# CY8C5868AXI_LP035 register map
File version: 0.1
CY8C58LP
Registers are 8-bit, read-write, no defined reset value unless marked. A register's access mark holds for its fields unless they carry their own. Offsets are from the block's base; lines under a group give offsets from that group; [hi:lo] are bit positions; {n}, {i} and the like mark numbered series; 'fields as' and 'values as' point back to an identical list; <NAME> marks a mode.

## Memory map
0x00000000 RECIBE — UART
0x00000000 EMITE — UART

## RECIBE — UART
Base 0x00000000
0x40006425 HD_RECIBE_RX_ADDRESS1 — RX Address1 Register
0x40006435 HD_RECIBE_RX_ADDRESS2 — RX Address2 Register
0x40006445 HD_RECIBE_RX_DATA — RX Data Register
0x40006455 HD_RECIBE_TX_DATA — TX Data Register
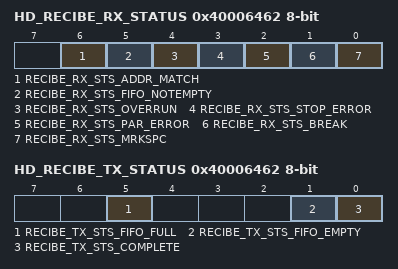
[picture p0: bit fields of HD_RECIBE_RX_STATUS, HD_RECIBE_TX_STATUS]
0x40006462 HD_RECIBE_RX_STATUS — RX status register
  [6] RECIBE_RX_STS_ADDR_MATCH ro, [5] RECIBE_RX_STS_FIFO_NOTEMPTY ro, [4] RECIBE_RX_STS_OVERRUN ro, [3] RECIBE_RX_STS_STOP_ERROR ro, [2] RECIBE_RX_STS_PAR_ERROR ro, [1] RECIBE_RX_STS_BREAK ro, [0] RECIBE_RX_STS_MRKSPC ro
0x40006462 HD_RECIBE_TX_STATUS — TX status register
  [5] RECIBE_TX_STS_FIFO_FULL ro, [1] RECIBE_TX_STS_FIFO_EMPTY ro, [0] RECIBE_TX_STS_COMPLETE ro

## EMITE — UART
Base 0x00000000
0x40006427 HD_EMITE_RX_ADDRESS1 — RX Address1 Register
0x40006437 HD_EMITE_RX_ADDRESS2 — RX Address2 Register
0x40006447 HD_EMITE_RX_DATA — RX Data Register
0x40006457 HD_EMITE_TX_DATA — TX Data Register
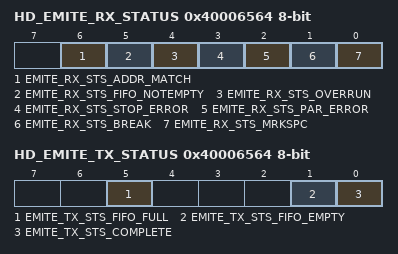
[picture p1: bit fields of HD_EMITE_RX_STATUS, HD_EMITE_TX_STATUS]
0x40006564 HD_EMITE_RX_STATUS — RX status register
  [6] EMITE_RX_STS_ADDR_MATCH ro, [5] EMITE_RX_STS_FIFO_NOTEMPTY ro, [4] EMITE_RX_STS_OVERRUN ro, [3] EMITE_RX_STS_STOP_ERROR ro, [2] EMITE_RX_STS_PAR_ERROR ro, [1] EMITE_RX_STS_BREAK ro, [0] EMITE_RX_STS_MRKSPC ro
0x40006564 HD_EMITE_TX_STATUS — TX status register
  [5] EMITE_TX_STS_FIFO_FULL ro, [1] EMITE_TX_STS_FIFO_EMPTY ro, [0] EMITE_TX_STS_COMPLETE ro
